VERSION ""

NS_ :

BS_:

BU_: AEC_REAR_HITCH_01 AEC_TRAILER_01

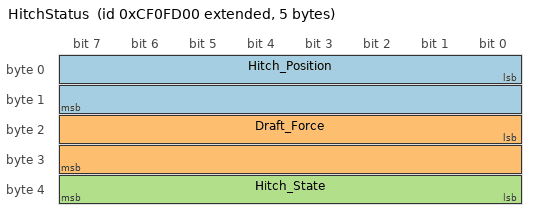
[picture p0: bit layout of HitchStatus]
BO_ 2364603648 HitchStatus: 5 AEC_REAR_HITCH_01
 SG_ Hitch_Position : 0|16@1+ (0.01,0) [0|100] "%" Vector__XXX
 SG_ Draft_Force : 16|16@1+ (1,0) [0|65535] "" Vector__XXX
 SG_ Hitch_State : 32|8@1+ (1,0) [0|7] "" Vector__XXX
